# ATSAMC21N18A register map
Registers are 32-bit, access not given, no defined reset value unless marked. A register's access mark holds for its fields unless they carry their own. Addresses are absolute; registers are grouped by the start of their names; [hi:lo] are bit positions; {n}, {i} and the like mark numbered series; 'fields as' and 'values as' point back to an identical list.

## CAN0
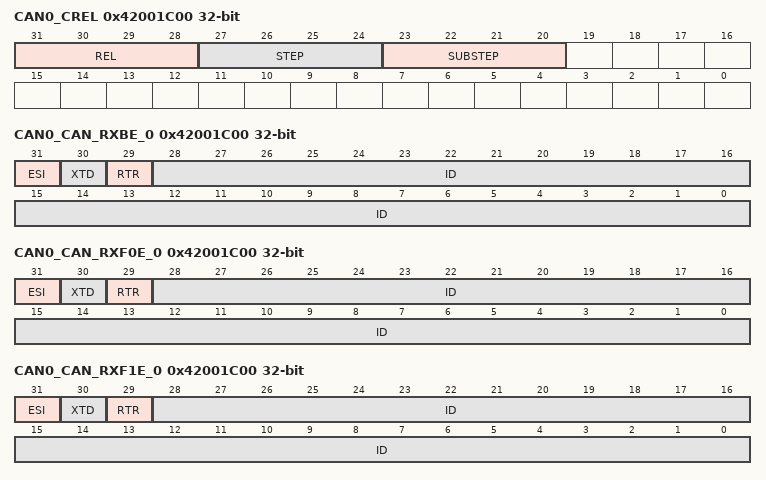
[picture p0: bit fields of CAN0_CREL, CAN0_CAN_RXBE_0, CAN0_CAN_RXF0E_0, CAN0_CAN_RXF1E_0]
0x42001C00 CAN0_CREL — Core Release
  [31:28] REL, [27:24] STEP, [23:20] SUBSTEP
0x42001C00 CAN0_CAN_RXBE_0 — Rx Buffer Element 0
  [31] ESI, [30] XTD, [29] RTR, [28:0] ID
0x42001C00 CAN0_CAN_RXF0E_0 — Rx FIFO 0 Element 0
  [31] ESI, [30] XTD, [29] RTR, [28:0] ID
0x42001C00 CAN0_CAN_RXF1E_0 — Rx FIFO 1 Element 0
  [31] ESI, [30] XTD, [29] RTR, [28:0] ID
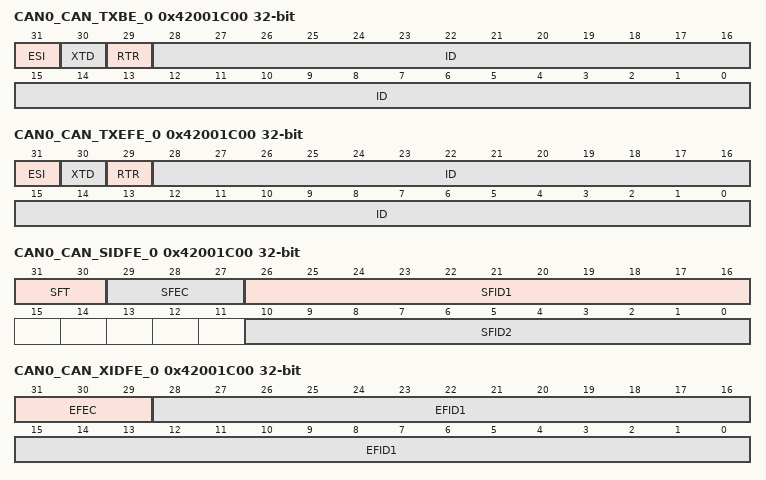
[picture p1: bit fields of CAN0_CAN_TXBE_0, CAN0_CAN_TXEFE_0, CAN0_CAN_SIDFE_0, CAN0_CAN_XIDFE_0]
0x42001C00 CAN0_CAN_TXBE_0 — Tx Buffer Element 0
  [31] ESI, [30] XTD, [29] RTR, [28:0] ID
0x42001C00 CAN0_CAN_TXEFE_0 — Tx Event FIFO Element 0
  [31] ESI, [30] XTD, [29] RTR, [28:0] ID
0x42001C00 CAN0_CAN_SIDFE_0 — Standard Message ID Filter Element 0
  [31:30] SFT, [29:27] SFEC, [26:16] SFID1, [10:0] SFID2
0x42001C00 CAN0_CAN_XIDFE_0 — Extended Message ID Filter Element 0
  [31:29] EFEC, [28:0] EFID1
0x42001C04 CAN0_ENDN — Endian
  [31:0] ETV
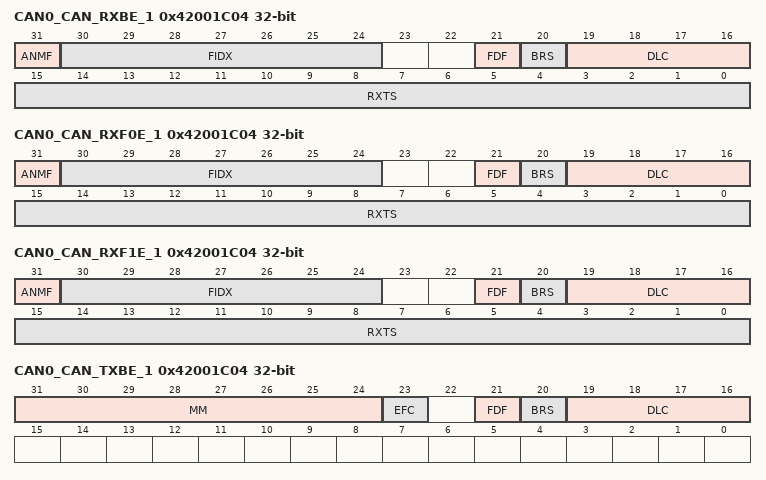
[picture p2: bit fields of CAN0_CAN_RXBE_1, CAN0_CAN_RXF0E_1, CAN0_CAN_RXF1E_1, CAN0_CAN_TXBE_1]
0x42001C04 CAN0_CAN_RXBE_1 — Rx Buffer Element 1
  [31] ANMF, [30:24] FIDX, [21] FDF, [20] BRS, [19:16] DLC, [15:0] RXTS
0x42001C04 CAN0_CAN_RXF0E_1 — Rx FIFO 0 Element 1
  fields as CAN0_CAN_RXBE_1
0x42001C04 CAN0_CAN_RXF1E_1 — Rx FIFO 1 Element 1
  fields as CAN0_CAN_RXBE_1
0x42001C04 CAN0_CAN_TXBE_1 — Tx Buffer Element 1
  [31:24] MM, [23] EFC, [21] FDF, [20] BRS, [19:16] DLC
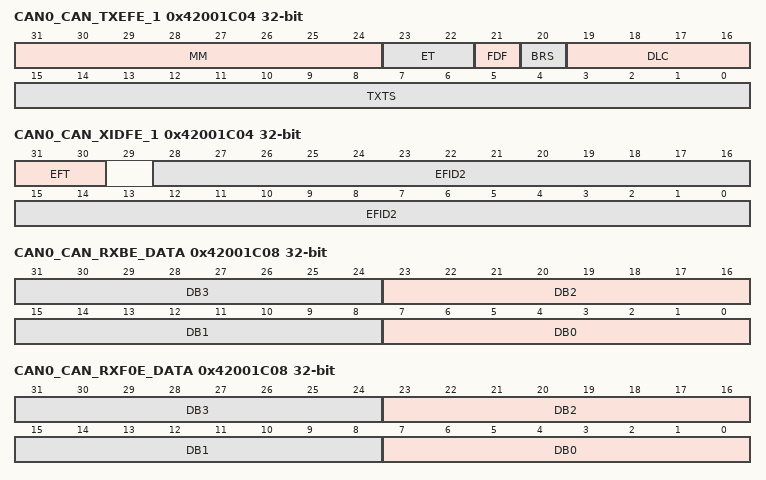
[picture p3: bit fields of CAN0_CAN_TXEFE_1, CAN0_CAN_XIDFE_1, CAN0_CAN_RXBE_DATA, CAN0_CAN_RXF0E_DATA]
0x42001C04 CAN0_CAN_TXEFE_1 — Tx Event FIFO Element 1
  [31:24] MM, [23:22] ET, [21] FDF, [20] BRS, [19:16] DLC, [15:0] TXTS
0x42001C04 CAN0_CAN_XIDFE_1 — Extended Message ID Filter Element 1
  [31:30] EFT, [28:0] EFID2
0x42001C08 CAN0_MRCFG — Message RAM Configuration
  [1:0] QOS
0x42001C08 CAN0_CAN_RXBE_DATA — Rx Buffer Element Data
  [8n+7:8n] DB{n} (n=0..3)
0x42001C08 CAN0_CAN_RXF0E_DATA — Rx FIFO 0 Element Data
  [8n+7:8n] DB{n} (n=0..3)
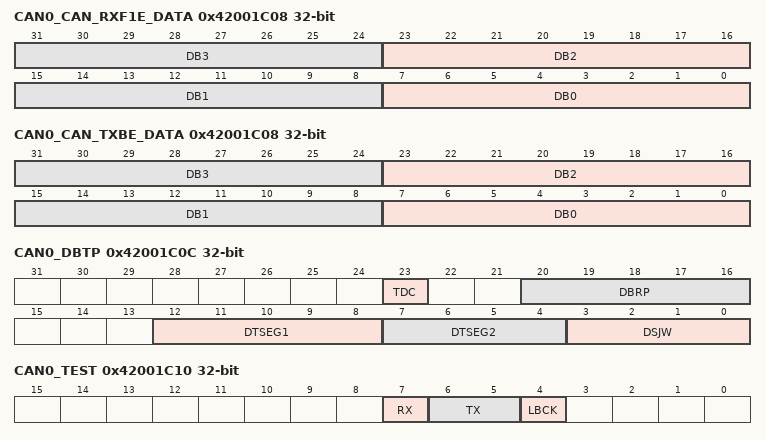
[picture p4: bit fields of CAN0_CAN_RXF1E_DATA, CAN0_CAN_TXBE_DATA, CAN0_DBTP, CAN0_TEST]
0x42001C08 CAN0_CAN_RXF1E_DATA — Rx FIFO 1 Element Data
  [8n+7:8n] DB{n} (n=0..3)
0x42001C08 CAN0_CAN_TXBE_DATA — Tx Buffer Element Data
  [8n+7:8n] DB{n} (n=0..3)
0x42001C0C CAN0_DBTP — Fast Bit Timing and Prescaler
  [23] TDC, [20:16] DBRP, [12:8] DTSEG1, [7:4] DTSEG2, [3:0] DSJW
0x42001C10 CAN0_TEST — Test
  [7] RX, [6:5] TX, [4] LBCK
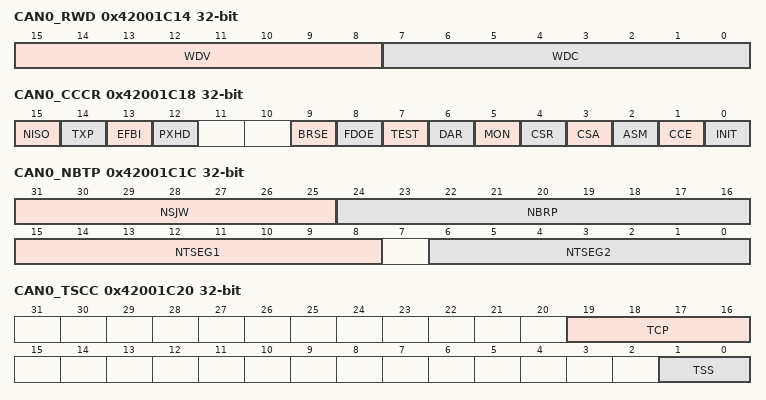
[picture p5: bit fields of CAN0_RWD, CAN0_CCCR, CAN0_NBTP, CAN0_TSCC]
0x42001C14 CAN0_RWD — RAM Watchdog
  [15:8] WDV, [7:0] WDC
0x42001C18 CAN0_CCCR — CC Control
  [15] NISO, [14] TXP, [13] EFBI, [12] PXHD, [9] BRSE, [8] FDOE, [7] TEST, [6] DAR, [5] MON, [4] CSR, [3] CSA, [2] ASM, [1] CCE, [0] INIT
0x42001C1C CAN0_NBTP — Nominal Bit Timing and Prescaler
  [31:25] NSJW, [24:16] NBRP, [15:8] NTSEG1, [6:0] NTSEG2
0x42001C20 CAN0_TSCC — Timestamp Counter Configuration
  [19:16] TCP, [1:0] TSS
0x42001C24 CAN0_TSCV — Timestamp Counter Value
  [15:0] TSC
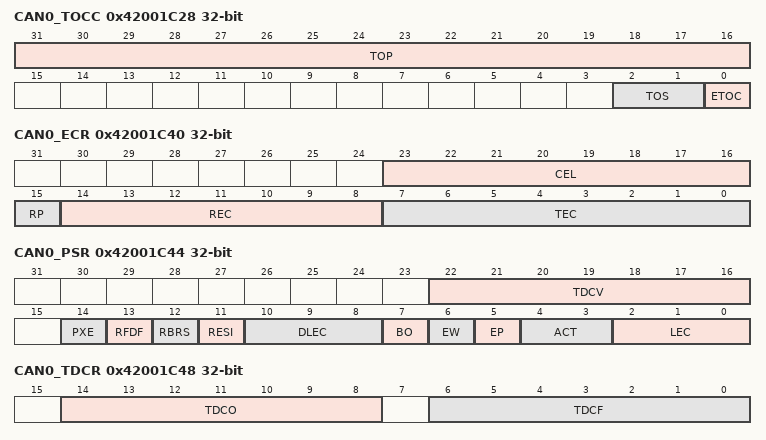
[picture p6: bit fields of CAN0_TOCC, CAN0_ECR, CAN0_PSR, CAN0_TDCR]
0x42001C28 CAN0_TOCC — Timeout Counter Configuration
  [31:16] TOP, [2:1] TOS, [0] ETOC
0x42001C2C CAN0_TOCV — Timeout Counter Value
  [15:0] TOC
0x42001C40 CAN0_ECR — Error Counter
  [23:16] CEL, [15] RP, [14:8] REC, [7:0] TEC
0x42001C44 CAN0_PSR — Protocol Status
  [22:16] TDCV, [14] PXE, [13] RFDF, [12] RBRS, [11] RESI, [10:8] DLEC, [7] BO, [6] EW, [5] EP, [4:3] ACT, [2:0] LEC
0x42001C48 CAN0_TDCR — Extended ID Filter Configuration
  [14:8] TDCO, [6:0] TDCF
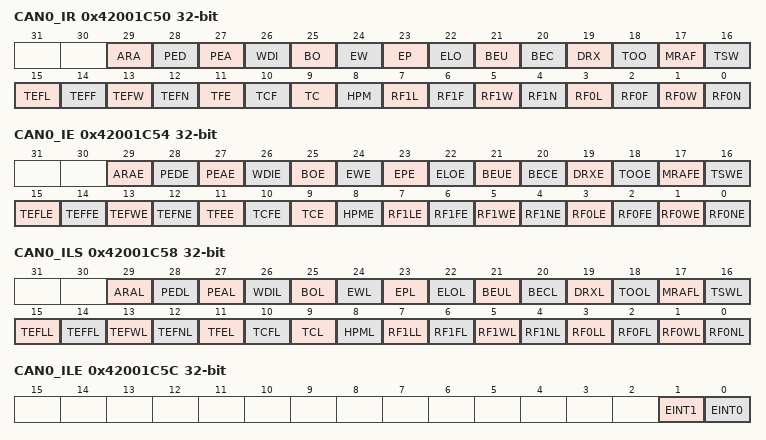
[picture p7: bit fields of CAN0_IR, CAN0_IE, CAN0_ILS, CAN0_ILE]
0x42001C50 CAN0_IR — Interrupt
  [29] ARA, [28] PED, [27] PEA, [26] WDI, [25] BO, [24] EW, [23] EP, [22] ELO, [21] BEU, [20] BEC, [19] DRX, [18] TOO, [17] MRAF, [16] TSW, [15] TEFL, [14] TEFF, [13] TEFW, [12] TEFN, [11] TFE, [10] TCF, [9] TC, [8] HPM, [7] RF1L, [6] RF1F, [5] RF1W, [4] RF1N, [3] RF0L, [2] RF0F, [1] RF0W, [0] RF0N
0x42001C54 CAN0_IE — Interrupt Enable
  [29] ARAE, [28] PEDE, [27] PEAE, [26] WDIE, [25] BOE, [24] EWE, [23] EPE, [22] ELOE, [21] BEUE, [20] BECE, [19] DRXE, [18] TOOE, [17] MRAFE, [16] TSWE, [15] TEFLE, [14] TEFFE, [13] TEFWE, [12] TEFNE, [11] TFEE, [10] TCFE, [9] TCE, [8] HPME, [7] RF1LE, [6] RF1FE, [5] RF1WE, [4] RF1NE, [3] RF0LE, [2] RF0FE, [1] RF0WE, [0] RF0NE
0x42001C58 CAN0_ILS — Interrupt Line Select
  [29] ARAL, [28] PEDL, [27] PEAL, [26] WDIL, [25] BOL, [24] EWL, [23] EPL, [22] ELOL, [21] BEUL, [20] BECL, [19] DRXL, [18] TOOL, [17] MRAFL, [16] TSWL, [15] TEFLL, [14] TEFFL, [13] TEFWL, [12] TEFNL, [11] TFEL, [10] TCFL, [9] TCL, [8] HPML, [7] RF1LL, [6] RF1FL, [5] RF1WL, [4] RF1NL, [3] RF0LL, [2] RF0FL, [1] RF0WL, [0] RF0NL
0x42001C5C CAN0_ILE — Interrupt Line Enable
  [1] EINT1, [0] EINT0
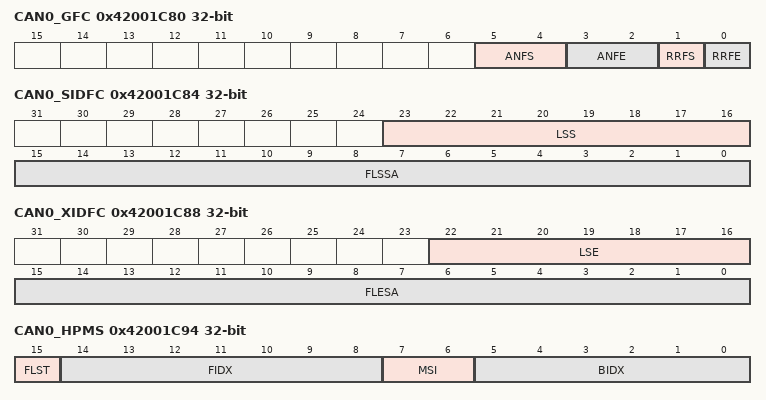
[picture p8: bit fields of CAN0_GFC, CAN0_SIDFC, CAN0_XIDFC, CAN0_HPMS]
0x42001C80 CAN0_GFC — Global Filter Configuration
  [5:4] ANFS, [3:2] ANFE, [1] RRFS, [0] RRFE
0x42001C84 CAN0_SIDFC — Standard ID Filter Configuration
  [23:16] LSS, [15:0] FLSSA
0x42001C88 CAN0_XIDFC — Extended ID Filter Configuration
  [22:16] LSE, [15:0] FLESA
0x42001C90 CAN0_XIDAM — Extended ID AND Mask
  [28:0] EIDM
0x42001C94 CAN0_HPMS — High Priority Message Status
  [15] FLST, [14:8] FIDX, [7:6] MSI, [5:0] BIDX
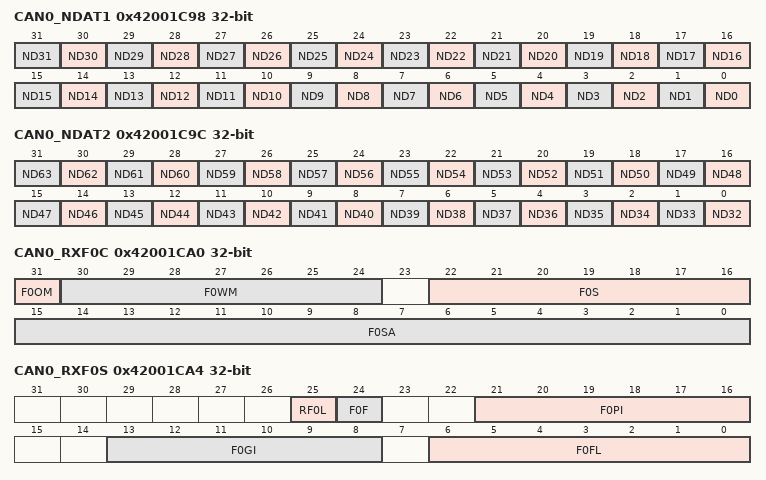
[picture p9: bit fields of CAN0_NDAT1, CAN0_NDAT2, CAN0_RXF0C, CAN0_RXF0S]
0x42001C98 CAN0_NDAT1 — New Data 1
  [n] ND{n} (n=0..31)
0x42001C9C CAN0_NDAT2 — New Data 2
  [n-32] ND{n} (n=32..63)
0x42001CA0 CAN0_RXF0C — Rx FIFO 0 Configuration
  [31] F0OM, [30:24] F0WM, [22:16] F0S, [15:0] F0SA
0x42001CA4 CAN0_RXF0S — Rx FIFO 0 Status
  [25] RF0L, [24] F0F, [21:16] F0PI, [13:8] F0GI, [6:0] F0FL
0x42001CA8 CAN0_RXF0A — Rx FIFO 0 Acknowledge
  [5:0] F0AI
0x42001CAC CAN0_RXBC — Rx Buffer Configuration
  [15:0] RBSA
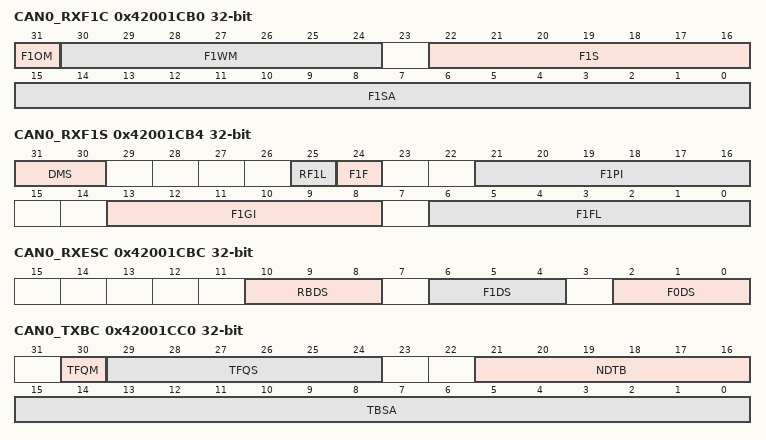
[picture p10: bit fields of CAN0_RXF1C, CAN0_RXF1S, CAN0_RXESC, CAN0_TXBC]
0x42001CB0 CAN0_RXF1C — Rx FIFO 1 Configuration
  [31] F1OM, [30:24] F1WM, [22:16] F1S, [15:0] F1SA
0x42001CB4 CAN0_RXF1S — Rx FIFO 1 Status
  [31:30] DMS, [25] RF1L, [24] F1F, [21:16] F1PI, [13:8] F1GI, [6:0] F1FL
0x42001CB8 CAN0_RXF1A — Rx FIFO 1 Acknowledge
  [5:0] F1AI
0x42001CBC CAN0_RXESC — Rx Buffer / FIFO Element Size Configuration
  [10:8] RBDS, [6:4] F1DS, [2:0] F0DS
0x42001CC0 CAN0_TXBC — Tx Buffer Configuration
  [30] TFQM, [29:24] TFQS, [21:16] NDTB, [15:0] TBSA
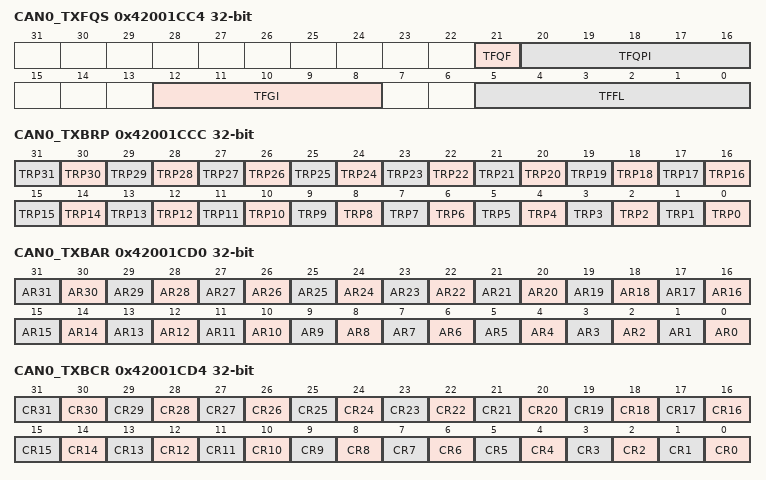
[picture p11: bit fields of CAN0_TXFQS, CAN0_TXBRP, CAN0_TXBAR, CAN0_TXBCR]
0x42001CC4 CAN0_TXFQS — Tx FIFO / Queue Status
  [21] TFQF, [20:16] TFQPI, [12:8] TFGI, [5:0] TFFL
0x42001CC8 CAN0_TXESC — Tx Buffer Element Size Configuration
  [2:0] TBDS
0x42001CCC CAN0_TXBRP — Tx Buffer Request Pending
  [n] TRP{n} (n=0..31)
0x42001CD0 CAN0_TXBAR — Tx Buffer Add Request
  [n] AR{n} (n=0..31)
0x42001CD4 CAN0_TXBCR — Tx Buffer Cancellation Request
  [n] CR{n} (n=0..31)
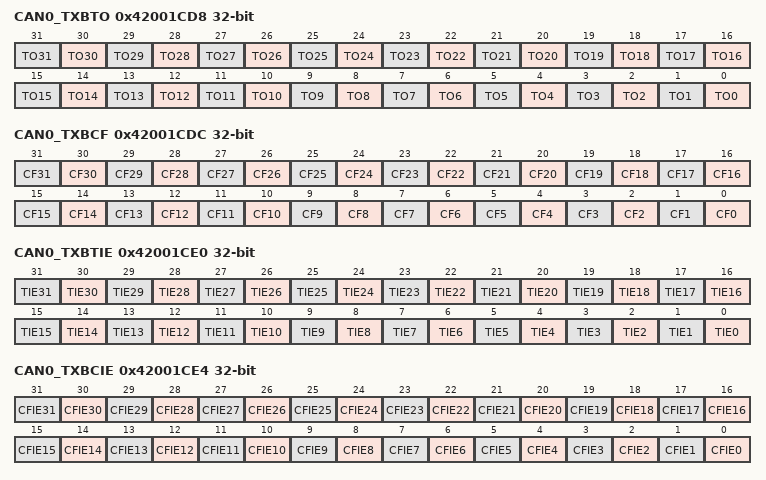
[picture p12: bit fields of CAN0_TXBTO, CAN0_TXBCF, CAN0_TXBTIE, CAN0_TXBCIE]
0x42001CD8 CAN0_TXBTO — Tx Buffer Transmission Occurred
  [n] TO{n} (n=0..31)
0x42001CDC CAN0_TXBCF — Tx Buffer Cancellation Finished
  [n] CF{n} (n=0..31)
0x42001CE0 CAN0_TXBTIE — Tx Buffer Transmission Interrupt Enable
  [n] TIE{n} (n=0..31)
0x42001CE4 CAN0_TXBCIE — Tx Buffer Cancellation Finished Interrupt Enable
  [n] CFIE{n} (n=0..31)
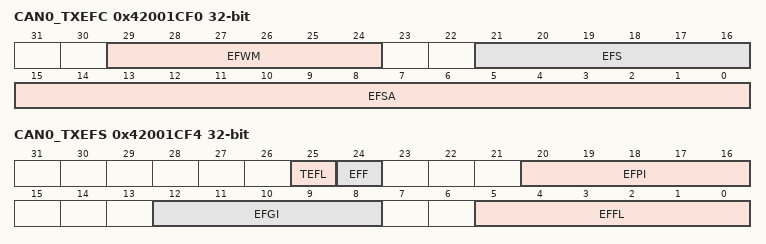
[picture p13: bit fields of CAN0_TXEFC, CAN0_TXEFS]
0x42001CF0 CAN0_TXEFC — Tx Event FIFO Configuration
  [29:24] EFWM, [21:16] EFS, [15:0] EFSA
0x42001CF4 CAN0_TXEFS — Tx Event FIFO Status
  [25] TEFL, [24] EFF, [20:16] EFPI, [12:8] EFGI, [5:0] EFFL
0x42001CF8 CAN0_TXEFA — Tx Event FIFO Acknowledge
  [4:0] EFAI
